# MAX32600 register map
File version: 1.0
Registers are 32-bit, read-write, reset 0x0 unless marked. A register's access mark holds for its fields unless they carry their own. Offsets are from the block's base; [hi:lo] are bit positions; {n}, {i} and the like mark numbered series; 'fields as' and 'values as' point back to an identical list.

## IOMAN — System I/O Manager
Base 0x40090C00
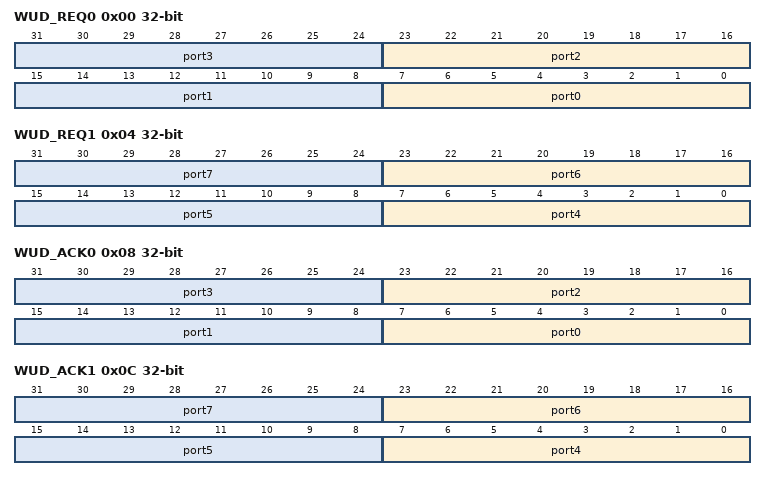
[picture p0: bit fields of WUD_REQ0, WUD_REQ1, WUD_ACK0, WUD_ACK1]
0x00 WUD_REQ0 — Wakeup Detect Mode Request Register 0 (P0/P1/P2/P3)
  [8n+7:8n] port{n} (n=0..3) — Wakeup Detect Request Mode: P{n}[7:0]
0x04 WUD_REQ1 — Wakeup Detect Mode Request Register 1 (P4/P5/P6/P7)
  [8n-25:8n-32] port{n} (n=4..7) — Wakeup Detect Request Mode: P{n}[7:0]
0x08 WUD_ACK0 — Wakeup Detect Mode Acknowledge Register 0 (P0/P1/P2/P3)
  [8n+7:8n] port{n} ro (n=0..3) — WUD Mode Acknowledge: P{n}[7:0]
0x0C WUD_ACK1 — Wakeup Detect Mode Acknowledge Register 1 (P4/P5/P6/P7)
  [8n-25:8n-32] port{n} ro (n=4..7) — WUD Mode Acknowledge: P{n}[7:0]
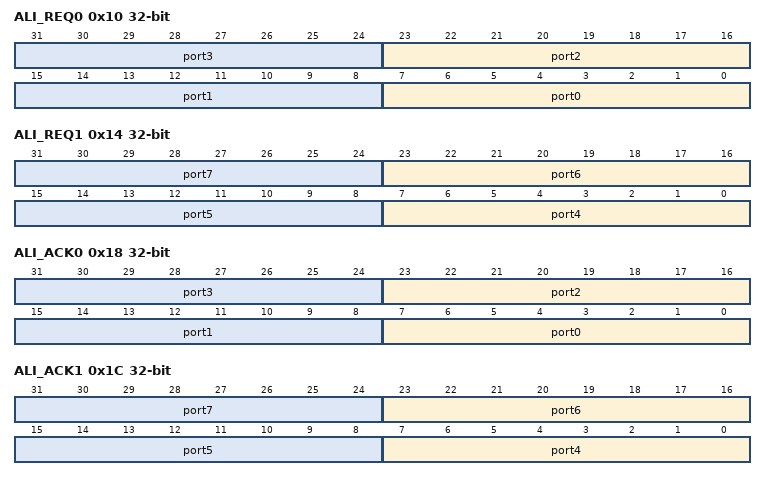
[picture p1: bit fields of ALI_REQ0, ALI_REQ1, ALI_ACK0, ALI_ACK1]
0x10 ALI_REQ0 — Analog Input Request Register 0 (P0/P1/P2/P3)
  [8n+7:8n] port{n} (n=0..3) — Analog Input Mode Request: P{n}[7:0]
0x14 ALI_REQ1 — Analog Input Request Register 1 (P4/P5/P6/P7)
  [8n-25:8n-32] port{n} (n=4..7) — Analog Input Mode Request: P{n}[7:0]
0x18 ALI_ACK0 — Analog Input Acknowledge Register 0 (P0/P1/P2/P3)
  [8n+7:8n] port{n} ro (n=0..3) — Analog In Mode Acknowledge: P{n}[7:0]
0x1C ALI_ACK1 — Analog Input Acknowledge Register 1 (P4/P5/P6/P7)
  [8n-25:8n-32] port{n} ro (n=4..7) — Analog In Mode Acknowledge: P{n}[7:0]
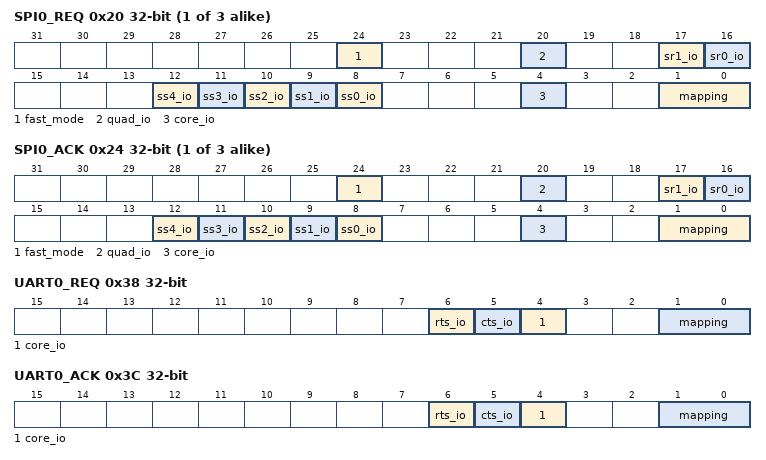
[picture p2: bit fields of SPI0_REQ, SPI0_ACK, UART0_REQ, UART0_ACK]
{0x20+8i} SPI{i}_REQ (i=0..2) — SPI{i} I/O Mode Request
  [24] fast_mode — SPI{i} Fast Mode
  [20] quad_io — SPI{i} Quad I/O Request
  [17] sr1_io — SPI{i} SR[1] I/O Request
  [16] sr0_io — SPI{i} SR[0] I/O Request
  [n+8] ss{n}_io (n=0..4) — SPI{i} SS[{n}] I/O Request
  [4] core_io — SPI{i} Core I/O Request
  [1:0] mapping — SPI{i} I/O Mapping Select
{0x24+8i} SPI{i}_ACK (i=0..2) — SPI{i} I/O Mode Acknowledge
  [24] fast_mode ro — SPI{i} Fast Mode Acknowledge
  [20] quad_io ro — SPI{i} Quad I/O Acknowledge
  [17] sr1_io ro — SPI{i} SR[1] I/O Acknowledge
  [16] sr0_io ro — SPI{i} SR[0] I/O Acknowledge
  [n+8] ss{n}_io ro (n=0..4) — SPI{i} SS[{n}] I/O Acknowledge
  [4] core_io ro — SPI{i} Core I/O Acknowledge
  [1:0] mapping ro — SPI{i} I/O Mapping Acknowledge
0x38 UART0_REQ — UART0 I/O Mode Request
  [6] rts_io — UART0 RTS I/O Request
  [5] cts_io — UART0 CTS I/O Request
  [4] core_io — UART0 Core I/O (RX/TX) Request
  [1:0] mapping — UART0 I/O Mapping Select
0x3C UART0_ACK — UART0 I/O Mode Acknowledge
  [6] rts_io ro — UART0 RTS I/O Acknowledge
  [5] cts_io ro — UART0 CTS I/O Acknowledge
  [4] core_io ro — UART0 Core I/O (RX/TX) Acknowledge
  [1:0] mapping ro — UART0 I/O Mapping Acknowledge
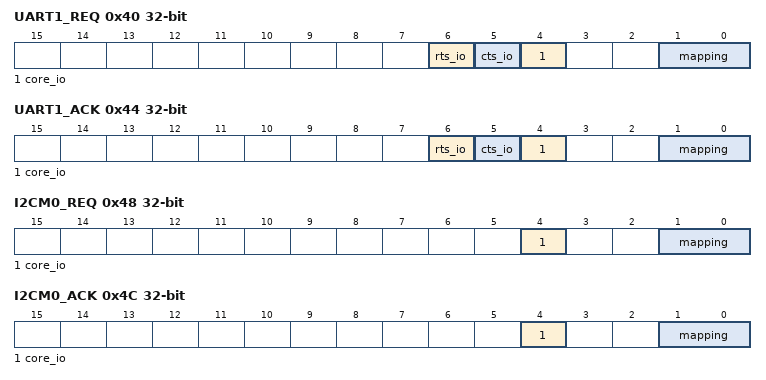
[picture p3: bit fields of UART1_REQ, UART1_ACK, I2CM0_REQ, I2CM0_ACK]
0x40 UART1_REQ — UART1 I/O Mode Request
  [6] rts_io — UART1 RTS I/O Request
  [5] cts_io — UART1 CTS I/O Request
  [4] core_io — UART1 Core I/O (RX/TX) Request
  [1:0] mapping — UART1 I/O Mapping Select
0x44 UART1_ACK — UART1 I/O Mode Acknowledge
  [6] rts_io ro — UART1 RTS I/O Acknowledge
  [5] cts_io ro — UART1 CTS I/O Acknowledge
  [4] core_io ro — UART1 Core I/O (RX/TX) Acknowledge
  [1:0] mapping ro — UART0 I/O Mapping Acknowledge
0x48 I2CM0_REQ — I2C Master 0 I/O Request
  [4] core_io — I2C Master I/O Request
  [1:0] mapping — I2C Master I/O Mapping Select
0x4C I2CM0_ACK — I2C Master 0 I/O Acknowledge
  [4] core_io ro — I2C Master I/O Acknowledge
  [1:0] mapping ro — I2C Master I/O Mapping Acknowledge
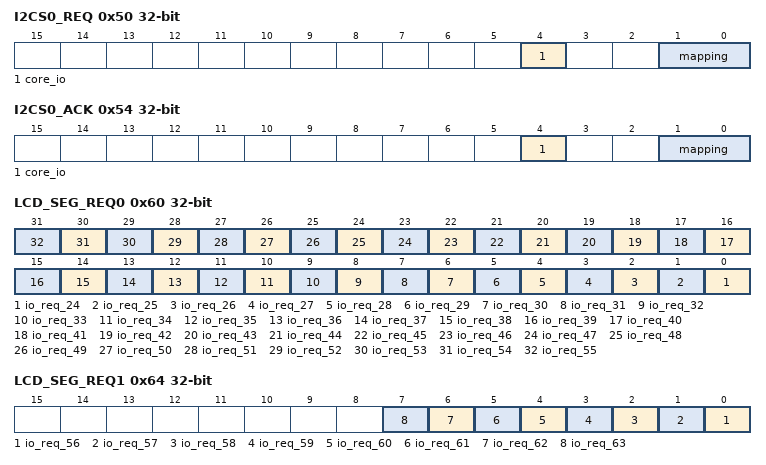
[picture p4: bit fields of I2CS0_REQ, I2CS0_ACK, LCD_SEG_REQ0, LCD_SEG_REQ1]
0x50 I2CS0_REQ — I2C Slave 0 I/O Request
  [4] core_io — I2C Slave I/O Request
  [1:0] mapping — I2C Slave I/O Mapping Select
0x54 I2CS0_ACK — I2C Slave 0 I/O Acknowledge
  [4] core_io ro — I2C Slave I/O Acknowledge
  [1:0] mapping ro — I2C Slave I/O Mapping Acknowledge
0x58 LCD_COM_REQ — LCD COM Driver I/O Request
  [0] com_io — LCD COM I/O Request
0x5C LCD_COM_ACK — LCD COM Driver I/O Acknowledge
  [0] com_io ro — LCD COM I/O Acknowledge
0x60 LCD_SEG_REQ0 — LCD SEG Driver I/O Request Register 0
  [n-24] io_req_{n} (n=24..55) — LCD SEG I/O Request for GPIO {n}
0x64 LCD_SEG_REQ1 — LCD SEG Driver I/O Request Register 1
  [n-56] io_req_{n} (n=56..63) — LCD SEG I/O Request for GPIO {n}
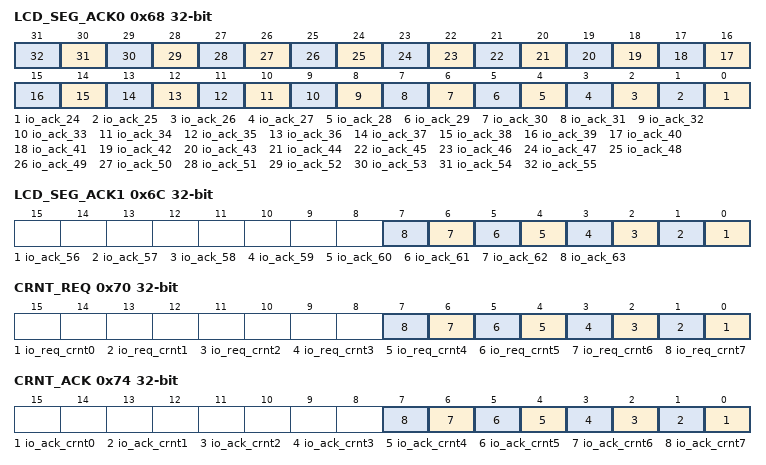
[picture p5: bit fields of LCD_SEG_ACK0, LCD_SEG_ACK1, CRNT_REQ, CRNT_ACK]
0x68 LCD_SEG_ACK0 — LCD SEG Driver I/O Acknowledge Register 0
  [n-24] io_ack_{n} ro (n=24..55) — LCD SEG I/O Acknowledge for GPIO {n}
0x6C LCD_SEG_ACK1 — LCD SEG Driver I/O Acknowledge Register 1
  [n-56] io_ack_{n} ro (n=56..63) — LCD SEG I/O Acknowledge for GPIO {n}
0x70 CRNT_REQ — Current Drive I/O Request Register
  [n] io_req_crnt{n} (n=0..7) — Request for pair CRNT{n}
0x74 CRNT_ACK — Current Drive I/O Acknowledge Register
  [n] io_ack_crnt{n} ro (n=0..7) — Acknowledge for pair CRNT{n}
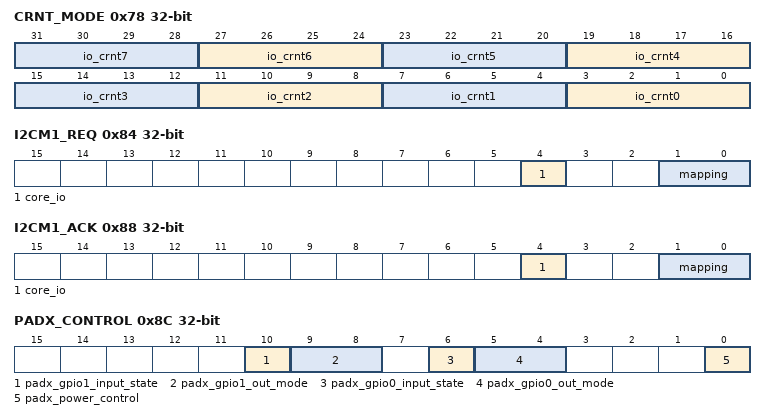
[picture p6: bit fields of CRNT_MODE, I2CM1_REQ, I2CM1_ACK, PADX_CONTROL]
0x78 CRNT_MODE — Current Drive I/O Mode Control
  [4n+3:4n] io_crnt{n} (n=0..7) — Current Drive Mode Select for pair CRNT{n}
0x7C ALI_CONNECT0 — Analog I/O Connection Control Register 0
0x80 ALI_CONNECT1 — Analog I/O Connection Control Register 1
0x84 I2CM1_REQ — I2C Master 1 I/O Request
  fields as I2CM0_REQ
0x88 I2CM1_ACK — I2C Master 1 I/O Acknowledge
  fields as I2CM0_ACK
0x8C PADX_CONTROL — Multichip Interface Pad Control Register
  [10] padx_gpio1_input_state ro — PADX GPIO1 Input Value
  [9:8] padx_gpio1_out_mode
  [6] padx_gpio0_input_state ro — PADX GPIO0 Input Value
  [5:4] padx_gpio0_out_mode
  [0] padx_power_control
